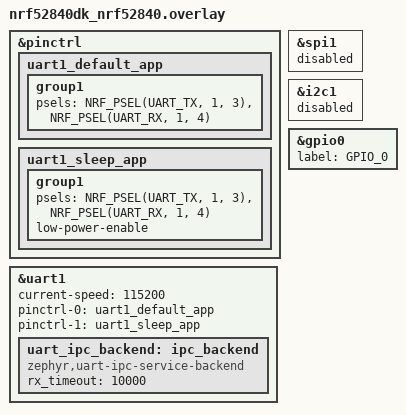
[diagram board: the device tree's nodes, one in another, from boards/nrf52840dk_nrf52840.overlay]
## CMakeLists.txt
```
#
# Copyright (c) 2021 Nordic Semiconductor
#
# SPDX-License-Identifier: LicenseRef-Nordic-5-Clause
#
cmake_minimum_required(VERSION 3.20.0)

find_package(Zephyr REQUIRED HINTS $ENV{ZEPHYR_BASE})
project(NONE)

# NORDIC SDK APP START
target_sources(app PRIVATE
  src/main.c
  src/ping_event.c
  src/pong_event.c
)
# NORDIC SDK APP END

# Add include directory for board specific CAF def files
zephyr_include_directories(
  src
  configuration/${BOARD}
)

add_subdirectory(drivers)
```

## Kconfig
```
#
# Copyright (c) 2021 Nordic Semiconductor ASA
#
# SPDX-License-Identifier: LicenseRef-Nordic-5-Clause
#

menu "Common Application Framework sample"

choice
    prompt "Ping or pong"
    config PING
        bool "Ping"
    config PONG
        bool "Pong"
endchoice

module = APPLICATION
module-str = application module
source "subsys/logging/Kconfig.template.log_config"

rsource "drivers/Kconfig"
endmenu

menu "Zephyr Kernel"
source "Kconfig.zephyr"
endmenu
```

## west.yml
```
manifest:
  version: "0.12"
  remotes:
      # nRF Connect SDK base URL.
    - name: ncs
      url-base: https://github.com/nrfconnect

  projects:
    - name: nrf
      remote: ncs
      repo-path: sdk-nrf
      revision: v2.1.0
      import: true

  self:
    path: distributed_events_poc
```

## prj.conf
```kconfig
#
# Copyright (c) 2021 Nordic Semiconductor
#
# SPDX-License-Identifier: LicenseRef-Nordic-5-Clause
#

CONFIG_PING=y
CONFIG_APPLICATION_LOG_LEVEL_DBG=y

# Dependencies for APP_EVENT_MANAGER and CAF
CONFIG_HEAP_MEM_POOL_SIZE=8192

CONFIG_APP_EVENT_MANAGER=y
CONFIG_APP_EVENT_MANAGER_LOG_LEVEL_ERR=y

CONFIG_EVENT_MANAGER_PROXY=y
CONFIG_APP_EVENT_MANAGER_PROVIDE_EVENT_SIZE=y

CONFIG_IPC_SERVICE=y

CONFIG_IPC_SERVICE_BACKEND_UART=y
CONFIG_UART_ASYNC_API=y

# CONFIG_HEAP_MEM_POOL_SIZE=4096

# Enable logging
CONFIG_LOG=y
CONFIG_IPC_BACKEND_UART_LOG_LEVEL_ERR=y

CONFIG_DEBUG=y
# Increase number of internal logging buffers
```

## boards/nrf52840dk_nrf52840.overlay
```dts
&pinctrl {
    uart1_default_app: uart1_default_app {
        group1{
            psels = <NRF_PSEL(UART_TX, 1, 3)>,<NRF_PSEL(UART_RX, 1, 4)>;
        };
    };
    uart1_sleep_app: uart1_sleep_app {
        group1{
            psels = <NRF_PSEL(UART_TX, 1, 3)>,<NRF_PSEL(UART_RX, 1, 4)>;
            low-power-enable;
        };
    };
};

&uart1 {
    status = "okay";
    current-speed = < 115200 >;
    pinctrl-0 = <&uart1_default_app>;
    pinctrl-1 = <&uart1_sleep_app>;
    pinctrl-names = "default", "sleep";

    uart_ipc_backend: ipc_backend {
        compatible = "zephyr,uart-ipc-service-backend";
        status = "okay";
        rx_timeout = <10000>;
    };
};

&spi1 {
    status = "disabled";
};

&i2c1 {
    status = "disabled";
};

&gpio0 {
    status = "okay";
    label = "GPIO_0";
};
```

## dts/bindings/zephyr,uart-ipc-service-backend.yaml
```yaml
description: |
  UART based ipc service backend.

compatible: "zephyr,uart-ipc-service-backend"

include: "uart-device.yaml"

properties:
  
  max_endpoint_name_length:
    type: int
    default: 32
    description: |
      Maximum length of the endpoint name.
  
  max_endpoint_count:
    type: int
    default: 1
    description: |
      Maximum number of endpoints.

  rx_timeout:
    type: int
    default: -1
    description: |
      Maximum allowed time between start of valid frames given in microseconds. Set to -1 to disable timeout.
```

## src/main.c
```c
/*
 * Copyright (c) 2021 Nordic Semiconductor ASA
 *
 * SPDX-License-Identifier: LicenseRef-Nordic-5-Clause
 */

#include <app_event_manager.h>
#include <event_manager_proxy.h>
#include <ipc/ipc_service.h>

#include "ping_event.h"
#include "pong_event.h"

#define MODULE APPLICATION

#ifdef CONFIG_PING
#define SUBSCRIBE_TO_EVENT pong_event
#endif

#ifdef CONFIG_PONG
#define SUBSCRIBE_TO_EVENT ping_event
#endif

#include <zephyr/logging/log.h>
LOG_MODULE_REGISTER(MODULE, CONFIG_APPLICATION_LOG_LEVEL);

void main(void) {
    const struct device *instance = DEVICE_DT_GET(DT_NODELABEL(uart_ipc_backend));
    if (!device_is_ready(instance)) {
        LOG_ERR("IPC service backend is not ready");
        return;
    }

    if (app_event_manager_init()) {
        LOG_ERR("Application Event Manager not initialized");
        return;
    }

    int err = event_manager_proxy_add_remote(instance);
    if (err) {
        LOG_ERR("IPC service register endpoint failed with error %d", err);
        return;
    }
    k_sleep(K_MSEC(1000));

    err = EVENT_MANAGER_PROXY_SUBSCRIBE(instance, SUBSCRIBE_TO_EVENT);

    if (err) {
        LOG_ERR("Proxy subscribe failed with error %d", err);
        return;
    }

    err = event_manager_proxy_start();
    if (err) {
        LOG_ERR("IPC service start failed with error %d", err);
        return;
    }
    event_manager_proxy_wait_for_remotes(K_FOREVER);
    k_sleep(K_MSEC(200));

#ifdef CONFIG_PING
    LOG_DBG("Sending first ping event!");
    struct ping_event *event = new_ping_event();
    strncpy(&event->message[0], "This is the first PING event!", sizeof(event->message));
    event->counter = 0;
    APP_EVENT_SUBMIT(event);
#endif /* CONFIG_PING */
}

static bool app_event_handler(const struct app_event_header *aeh) {
    if (is_ping_event(aeh)) {
        const struct ping_event *event = cast_ping_event(aeh);
        LOG_INF("PING! (%d) : %s",event->counter, event->message);
        // k_sleep(K_MSEC(500));
        struct pong_event *pong = new_pong_event();
        strncpy(&pong->message[0], "Hello from the PONG server!", sizeof(pong->message));
        pong->counter = event->counter + 1;
        APP_EVENT_SUBMIT(pong);
        LOG_INF("Sending PONG!");
        return false;
    }

    if (is_pong_event(aeh)) {
        const struct pong_event *event = cast_pong_event(aeh);
        LOG_INF("PONG! (%d) : %s",event->counter, event->message);
        // k_sleep(K_MSEC(500));
        struct ping_event *ping = new_ping_event();
        strncpy(&ping->message[0], "Hello from the PING client!", sizeof(ping->message));
        ping->counter = event->counter + 1;
        APP_EVENT_SUBMIT(ping);
        LOG_INF("Sending PING!");
        return false;
    }

    return false;
}

APP_EVENT_LISTENER(MODULE, app_event_handler);
APP_EVENT_SUBSCRIBE(MODULE, SUBSCRIBE_TO_EVENT);
```

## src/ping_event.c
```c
#include "ping_event.h"

static void log_ping_event(const struct app_event_header *aeh) {
    const struct ping_event *event = cast_ping_event(aeh);

    APP_EVENT_MANAGER_LOG(aeh, "message: %s", event->message);
}

APP_EVENT_TYPE_DEFINE(ping_event, log_ping_event, NULL, APP_EVENT_FLAGS_CREATE());
```

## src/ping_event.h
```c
#include <app_event_manager.h>

struct ping_event {
    struct app_event_header header;
    char message[128];
    uint8_t counter;
};

APP_EVENT_TYPE_DECLARE(ping_event);
```

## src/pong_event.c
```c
#include "pong_event.h"

static void log_pong_event(const struct app_event_header *aeh) {
    const struct pong_event *event = cast_pong_event(aeh);

    APP_EVENT_MANAGER_LOG(aeh, "message: %s", event->message);
}

APP_EVENT_TYPE_DEFINE(pong_event, log_pong_event, NULL, APP_EVENT_FLAGS_CREATE());
```

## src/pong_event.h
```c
#include <app_event_manager.h>

struct pong_event {
    struct app_event_header header;
    char message[128];
    uint8_t counter;
};

APP_EVENT_TYPE_DECLARE(pong_event);
```

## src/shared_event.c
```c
#include "shared_event.h"

static void log_shared_event(const struct app_event_header *aeh) {
    struct shared_event *event = cast_shared_event(aeh);

    APP_EVENT_MANAGER_LOG(aeh, "value: %d", event->value);
}

APP_EVENT_TYPE_DEFINE(shared_event, log_shared_event, NULL, APP_EVENT_FLAGS_CREATE());
```

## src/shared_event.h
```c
#include <app_event_manager.h>

struct shared_event {
    struct app_event_header header;
    int value;
};

APP_EVENT_TYPE_DECLARE(shared_event);
```
